# TZ10xx register map
File version: 0.1g
Registers are 32-bit, read-write, reset 0x0 unless marked. A register's access mark holds for its fields unless they carry their own. Offsets are from the block's base; [hi:lo] are bit positions.

## rtclv
Base 0x40040000
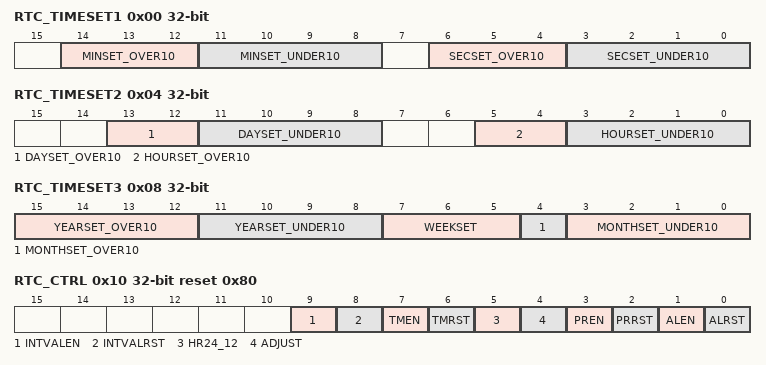
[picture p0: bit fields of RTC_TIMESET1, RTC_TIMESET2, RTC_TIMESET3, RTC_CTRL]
0x00 RTC_TIMESET1 — Time Set 1 Register
  [14:12] MINSET_OVER10 — Sets the minute counter (ten's place). The settable values are 0 to 5 (0b000 to 0b101). No other values can be set (writing disable).
  [11:8] MINSET_UNDER10 — Sets the minute counter (one's place). The settable values are 0 to 9 (0b0000 to 0b1001). No other values can be set (writing disable).
  [6:4] SECSET_OVER10 — Sets the second counter (ten's place). The settable values are 0 to 5 (0b000 to 0b101). No other values can be set (writing disable).
  [3:0] SECSET_UNDER10 — Sets the second counter (one's place). The settable values are 0 to 9 (0b0000 to 0b1001). No other values can be set (writing disable).
0x04 RTC_TIMESET2 — Time Set 2 Register
  [13:12] DAYSET_OVER10 — Sets the day counter (ten's place). The settable values are 0 to 3 (0b00 to 0b11).
  [11:8] DAYSET_UNDER10 — Sets the day counter (one's place). The settable values are 0 to 9 (0b0000 to 0b1001). No other values can be set (writing disable).
  [5:4] HOURSET_OVER10 — Sets the hour counter (ten's place). The settable values are 0 to 3 (0b00 to 0b11). (Note) In 12-hour mode, bit5 is used to differentiate AM/PM. So, to set the time in the afternoon, set bit5 to "1".
  [3:0] HOURSET_UNDER10 — Sets the hour counter (one's place). The settable values are 0 to 9 (0b0000 to 0b1001). No other values can be set (writing disable).
0x08 RTC_TIMESET3 — Time Set 3 Register
  [15:12] YEARSET_OVER10 — Sets the year counter (ten's place). The settable values are 0 to 9 (0b0000 to 0b1001). No other values can be set (writing disable).
  [11:8] YEARSET_UNDER10 — Sets the year counter (one's place). The settable values are 0 to 9 (0b0000 to 0b1001). No other values can be set (writing disable).
  [7:5] WEEKSET — Sets the day-of-week counter. 0b000: Sunday 0b001: Monday 0b010: Tuesday 0b011: Wednesday 0b100: Thursday 0b101: Friday 0b110: Saturday 0b111: Reserved (unsettable (writing disable))
  [4] MONTHSET_OVER10 — Sets the month counter (ten's place). The settable values are 0 and 1 (0b0 to 0b1).
  [3:0] MONTHSET_UNDER10 — Sets the month counter (one's place). The settable values are 0 to 9 (0b0000 to 0b1001). No other values can be set (writing disable).
0x0C RTC_TIMESET4 — Time Set 4 Register
  [1:0] LEAP — Sets the leap year ("0": leap year) The settable values are 0 to 3 (0b00 to 0b11).
0x10 RTC_CTRL reset 0x80 — Control Register
  [9] INTVALEN — Interval timer enable 0b1: Enable 0b0: Disable
  [8] INTVALRST — Loads the interval timer setting. After setting data loading is complete, 0 is automatically set. At writing: 0b1: Starts loading of the setting data. 0b0: No operation At reading: 0b1: Loading of the setting data is in progress. 0b0: Loading of the setting data is complete.
  [7] TMEN — RTC operation enable 0b1: Enable 0b0: Disable
  [6] TMRST — Loading the time counter with TIMESET1 to 4 register settings After loading of setting data to the time counter is complete, 0 is automatically set. At writing: 0b1: Starts loading of setting data. 0b0: No operation At reading: 0b1: Loading of the setting data is in progress. 0b0: Loading of setting data is complete.
  [5] HR24_12 — 24/12Hr selection 0b1: 24-hour notation 0b0: 12-hour notation
  [4] ADJUST — Time count adjustment After adjustment is complete, 0 is automatically set. At writing: 0b1: Starts adjustment. 0b0: No operation At reading: 0b1: Adjustment in progress 0b0: Adjustment completed
  [3] PREN — Periodic interrupt function enable 0b1: Enable 0b0: Disable
  [2] PRRST — Loads the periodic interrupt setting. After loading of setting data is complete, 0 is automatically set. At writing: 0b1: Starts loading of the setting data. 0b0: No operation At reading: 0b1: Loading of the setting data is in progress. 0b0: Loading of the setting data is complete.
  [1] ALEN — Alarm function enable 0b1: Enable 0b0: Disable
  [0] ALRST — Loads the alarm setting. After loading of setting data is complete, 0 is automatically set. At writing: 0b1: Starts loading of the setting data. 0b0: No operation At reading: 0b1: Loading of the setting data is in progress. 0b0: Loading of the setting data is complete.
0x14 RTC_STATUS ro
  [0] RTC_READY — If the RTC counter value becomes ready to be read, 1 is automatically set.
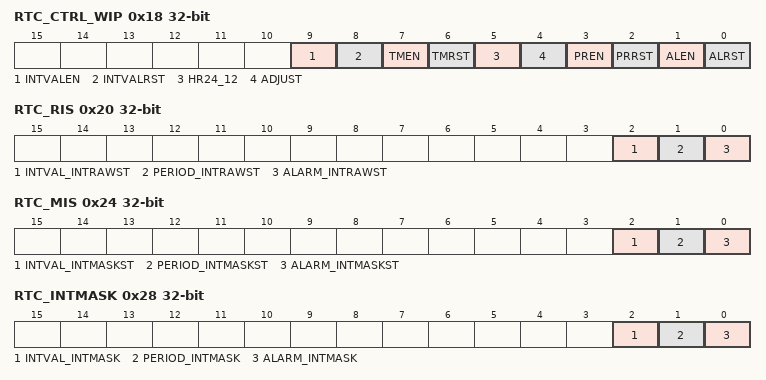
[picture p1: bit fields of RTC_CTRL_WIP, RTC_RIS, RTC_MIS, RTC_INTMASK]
0x18 RTC_CTRL_WIP ro — Control Register write access status
  [9] INTVALEN — [RTC_CTRL].INTVALEN bit status of write access 0b0:writable 0b1:not writable
  [8] INTVALRST — [RTC_CTRL].INTVALRST bit status of write access 0b0:writable 0b1:not writable
  [7] TMEN — [RTC_CTRL].TMEN bit status of write access 0b0:writable 0b1:not writable
  [6] TMRST — [RTC_CTRL].TMRST bit status of write access 0b0:writable 0b1:not writable
  [5] HR24_12 — [RTC_CTRL].HR24_12 bit status of write access 0b0:writable 0b1:not writable
  [4] ADJUST — [RTC_CTRL].ADJUST bit status of write access 0b0:writable 0b1:not writable
  [3] PREN — [RTC_CTRL].PREN bit status of write access 0b0:writable 0b1:not writable
  [2] PRRST — [RTC_CTRL].PRRST bit status of write access 0b0:writable 0b1:not writable
  [1] ALEN — [RTC_CTRL].ALEN bit status of write access 0b0:writable 0b1:not writable
  [0] ALRST — [RTC_CTRL].ALRST bit status of write access 0b0:writable 0b1:not writable
0x20 RTC_RIS ro — Raw Interrupt Status Register
  [2] INTVAL_INTRAWST — Interval-timer interrupt status 0b1: Interrupt request available 0b0: No interrupt request
  [1] PERIOD_INTRAWST — Periodic interrupt status 0b1: Interrupt request available 0b0: No interrupt request
  [0] ALARM_INTRAWST — Alarm interrupt status 0b1: Interrupt request available 0b0: No interrupt request
0x24 RTC_MIS ro — Masked Interrupt Status Register
  [2] INTVAL_INTMASKST — Interval-timer interrupt status 0b1: Interrupt request available 0b0: No interrupt request Not set when INTVAL_INTMASK=0.
  [1] PERIOD_INTMASKST — Periodic interrupt status 0b1: Interrupt request available 0b0: No interrupt request Not set when PERIOD_INTMASK=0.
  [0] ALARM_INTMASKST — Alarm interrupt status 0b1: Interrupt request available 0b0: No interrupt request Not set when ALARM_INTMASK=0.
0x28 RTC_INTMASK — Interrupt Mask Register
  [2] INTVAL_INTMASK — Interval-timer interrupt 0b1: No interrupt mask (interrupt enable) 0b0: Interrupt mask (interrupt disable)
  [1] PERIOD_INTMASK — Periodic interrupt 0b1: No interrupt mask (interrupt enable) 0b0: Interrupt mask (interrupt disable)
  [0] ALARM_INTMASK — Alarm interrupt 0b1: No interrupt mask (interrupt enable) 0b0: Interrupt mask (interrupt disable)
0x2C RTC_PERIODIC — Periodic Interrupt Set Register
  [3:0] PERIODIC_INTSET — Sets the periodic interrupt (every second, every minute, every hour, every day, every month) 0b0000: No periodic interrupt occurrence 0b0001: Every second (at the same time with second counting-up) 0b0010: 00 second every minute 0b0011: 00 minute 00 second every hour 0b0100: 00 hour 00 minute 00 second every day 0b0101: 00 hour 00 minute 00 second every month 0b0110: Reserved (unsettable (writing disable)) 0b0111: Reserved (unsettable (writing disable)) 0b1000: Every 1/2 second 0b1001: Every 1/4 second 0b1010: Every 1/8 second 0b1011: Every 1/16 second 0b1100: Every 1/32 second 0b1101: Every 1/64 second 0b1110: Every 1/128 second 0b1111: Every 1/256 second
0x30 RTC_PERIOD_INTCLR — Periodic Interrupt Clear
  [31:0] PERIOD_INTCLR — Clears the periodic interrupt. If a value is written to this register, the periodic interrupt is cleared, regardless of the value to be written.
0x34 RTC_ALARM_INTCLR — Alarm Interrupt Clear
  [31:0] ALARM_INTCLR — Clears the alarm interrupt. If a value is written to this register, the alarm interrupt is cleared, regardless of the value to be written.
0x38 RTC_INTVAL_INTCLR — Interval Interrupt Clear
  [31:0] INTVAL_INTCLR — Clears the interval-timer interrupt. If a value is written to this register, the interval-timer interrupt is cleared, regardless of the value to be written.
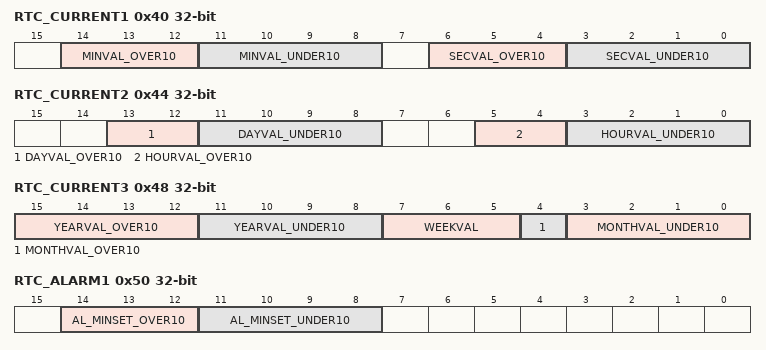
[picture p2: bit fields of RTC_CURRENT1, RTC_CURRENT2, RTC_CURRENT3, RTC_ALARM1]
0x40 RTC_CURRENT1 ro — Current Time 1 Register
  [14:12] MINVAL_OVER10 — Current value of the minute counter (ten's place)
  [11:8] MINVAL_UNDER10 — Current value of the minute counter (one's place)
  [6:4] SECVAL_OVER10 — Current value of the second counter (ten's place)
  [3:0] SECVAL_UNDER10 — Current value of the second counter (one's place)
0x44 RTC_CURRENT2 ro — Current Time 2 Register
  [13:12] DAYVAL_OVER10 — Current value of the day counter (ten's place)
  [11:8] DAYVAL_UNDER10 — Current value of the day counter (one's place)
  [5:4] HOURVAL_OVER10 — Current value of the hour counter (ten's place)
  [3:0] HOURVAL_UNDER10 — Current value of the hour counter (one's place)
0x48 RTC_CURRENT3 ro — Current Time 3 Register
  [15:12] YEARVAL_OVER10 — Current value of the year counter (ten's place)
  [11:8] YEARVAL_UNDER10 — Current value of the year counter (one's place)
  [7:5] WEEKVAL — Current value of the day-of-week counter
  [4] MONTHVAL_OVER10 — Current value of the month counter (ten's place)
  [3:0] MONTHVAL_UNDER10 — Current value of the month counter (one's place)
0x4C RTC_CURRENT4 ro — Current Time 4 Register
  [1:0] LEAP — Current value of the leap year counter
0x50 RTC_ALARM1 — Alarm Set 1 Register
  [14:12] AL_MINSET_OVER10 — Sets the minute counter (ten's place) for alarm. The settable values are 0 to 5 ((0b000 to 0b101). No other values can be set (writing disable).
  [11:8] AL_MINSET_UNDER10 — Sets the minute counter (one's place) for alarm. The settable values are 0 to 9 ((0b0000 to 0b1001). No other values can be set (writing disable).
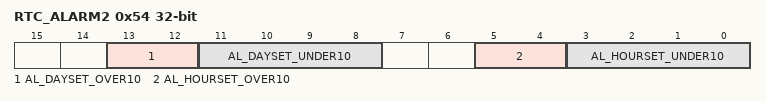
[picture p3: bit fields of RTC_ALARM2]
0x54 RTC_ALARM2 — Alarm Set 2 Register
  [13:12] AL_DAYSET_OVER10 — Sets the day counter (ten's place) for alarm. The settable values are 0 to 3 (0b00 to 0b11).
  [11:8] AL_DAYSET_UNDER10 — Sets the minute counter (one's place) for alarm. The settable values are 0 to 9 (0b0000 to 0b1001). No other values can be set (writing disable).
  [5:4] AL_HOURSET_OVER10 — Sets the hour counter (ten's place) for alarm. The settable values are 0 to 3 (0b00 to 0b11). (Note) In 12-hour mode, bit5 is used to differentiate AM/PM. So, to set the time in the afternoon, set bit5 to "1".
  [3:0] AL_HOURSET_UNDER10 — Sets the hour counter (one's place) for alarm. The settable values are 0 to 9 (0b0000 to 0b1001). No other values can be set (writing disable).
0x58 RTC_ALARM3 — Alarm Set 3 Register
  [7:5] AL_WEEKSET — Sets the day-of-week counter for alarm. 0b000: Sunday 0b001: Monday 0b010: Tuesday 0b011: Wednesday 0b100: Thursday 0b101: Friday 0b110: Saturday 0b111: Reserved
0x60 RTC_INTVAL_SET reset 0xFFFF — Interval Timer Set Register
  [15:0] INTVAL_SET — Sets the interval-timer interrupt generation time. This value is set with the number of cycles of the source clock (2.048kHz) of the timer. The time of (setting value + 1) cycles is the period that continues until interrupt generation. Setting of 0x0000 is prohibited.
0x64 RTC_INTVAL_TMR ro reset 0xFFFF
  [15:0] COUNT_VAL — Current value of interval-timer counter can be read.
